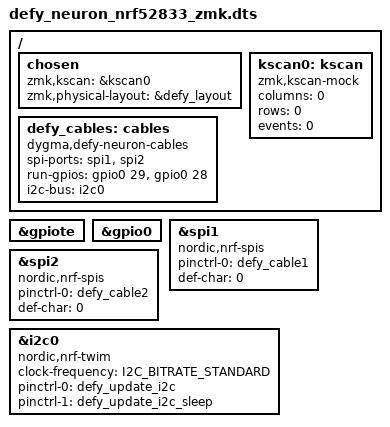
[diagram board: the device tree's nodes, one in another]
/*
 * The wireless Neuron as ZMK's split central, on top of
 * defy_neuron_nrf52833.dts. Pins follow Neuron 2 hardware V1.1.
 *
 * SPDX-License-Identifier: MIT
 */

#include "defy_neuron_nrf52833.dts"
/*
 * ZMK's boot mode in GPREGRET, where &defy_drive writes the UF2 loader's drive
 * request (<dygma/defy_loader.h>).
 */
#include <common/nordic/nrf52833_uf2_boot_mode.dtsi>
#include <zephyr/dt-bindings/gpio/gpio.h>

#include "../defy/defy-layouts.dtsi"

/ {
    chosen {
        zmk,kscan = &kscan0;
        zmk,physical-layout = &defy_layout;
    };

    /* The Neuron has no keys of its own. */
    kscan0: kscan {
        compatible = "zmk,kscan-mock";
        columns = <0>;
        rows = <0>;
        events = <0>;
    };

    /*
     * nRST2 (P0.29) is the left cable's RUN line and nRST1 (P0.28) the
     * right's. The dock raises nRST1, although the left half holds the Neuron
     * (docs/automatic-transports.md).
     */
    defy_cables: cables {
        compatible = "dygma,defy-neuron-cables";
        spi-ports = <&spi1 &spi2>;
        run-gpios = <&gpio0 29 GPIO_ACTIVE_HIGH>, <&gpio0 28 GPIO_ACTIVE_HIGH>;
        i2c-bus = <&i2c0>;
    };
};

&gpiote {
    status = "okay";
};

&gpio0 {
    status = "okay";
};

/* The cables' SPI slaves. */
&spi1 {
    compatible = "nordic,nrf-spis";
    status = "okay";
    pinctrl-0 = <&defy_cable1>;
    pinctrl-names = "default";
    def-char = <0>;
};

&spi2 {
    compatible = "nordic,nrf-spis";
    status = "okay";
    pinctrl-0 = <&defy_cable2>;
    pinctrl-names = "default";
    def-char = <0>;
};

/* To the halves' bootloaders, through both cables. */
&i2c0 {
    compatible = "nordic,nrf-twim";
    status = "okay";
    clock-frequency = <I2C_BITRATE_STANDARD>;
    pinctrl-0 = <&defy_update_i2c>;
    pinctrl-1 = <&defy_update_i2c_sleep>;
    pinctrl-names = "default", "sleep";
};
